# MPS2_SSE_200 register map
Vendor: ARM Ltd.; Series: ARMv8-M Mainline; File version: 1.0
CPU: CM33 r0p0, little endian, MPU, no FPU, 4 interrupt priority bits, 8 SAU regions
Registers are 32-bit, read-write, reset 0x0 unless marked. A register's access mark holds for its fields unless they carry their own. Offsets are from the block's base; [hi:lo] are bit positions; {n}, {i} and the like mark numbered series.

## SSP0 — SPI 0
Base 0x40205000
Same registers: SSP1 0x40206000, SSP2 0x40209000, SSP3 0x4020A000, SSP4 0x4020B000, SSP0_Secure 0x50205000, SSP1_Secure 0x50206000, SSP2_Secure 0x50209000, SSP3_Secure 0x5020A000, SSP4_Secure 0x5020B000
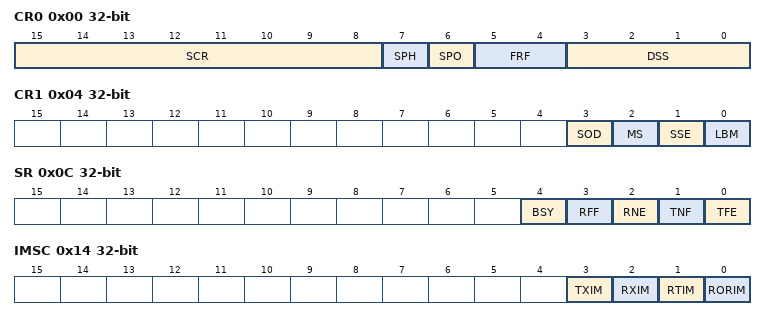
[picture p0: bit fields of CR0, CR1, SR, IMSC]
0x00 CR0 — Control register 0
  [15:8] SCR — Serial clock rate
  [7] SPH — SSPCLKOUT phase
  [6] SPO — SSPCLKOUT polarity
  [5:4] FRF — Frame format
    0=Motorola SPI frame format; 1=TI (TI synchronous serial frame format); 2=NM (National Microwire frame format)
  [3:0] DSS — Data Size Select
    {v}={v+1}-bit (v=3..15)
0x04 CR1 — Control register 1
  [3] SOD — Slave-mode output disable
    0=Enable (SSP can drive the SSPTXD output in slave mode); 1=Disable (SSP must not drive the SSPTXD output in slave mode)
  [2] MS — Master or slave mode select
    0=Master (Device configured as master, default); 1=Slave (Device configured as slave)
  [1] SSE — Synchronous serial port enable
    0=Disabled (SSP operation disabled); 1=Enabled (SSP operation enabled)
  [0] LBM — Loop back mode
    0=Normal serial port operation enabled; 1=Loopback (Output of transmit serial shifter is connected to input of receive serial shifter internally)
0x08 DR — Data register
  [15:0] Data — Transmit/Receive FIFO
0x0C SR — Status register
  [4] BSY — PrimeCell SSP busy flag
    0=Idle (SSP is idle); 1=Busy (SSP is currently transmitting and/or receiving a frame or the transmit FIFO is not empty)
  [3] RFF — Receive FIFO full
    0=NF (Receive FIFO is not full); 1=F (Receive FIFO is full)
  [2] RNE — Receive FIFO not empty
    0=E (Receive FIFO is empty); 1=NE (Receive FIFO is not empty)
  [1] TNF — Transmit FIFO not full
    0=F (Receive FIFO is full); 1=NF (Receive FIFO is not full)
  [0] TFE — Transmit FIFO empty
    0=NE (Receive FIFO is not empty); 1=E (Receive FIFO is empty)
0x10 CPSR — Clock prescale register
  [7:0] CPSDVSR — Clock prescale divisor
0x14 IMSC — Interrupt mask set or clear register
  [3] TXIM — Transmit FIFO interrupt mask
    0=Masked (Transmit FIFO half empty or less condition interrupt is masked); 1=Not Masked (Transmit FIFO half empty or less condition interrupt is not masked)
  [2] RXIM — Receive FIFO interrupt mask
    0=Masked (Receive FIFO half full or less condition interrupt is masked); 1=Not Masked (Receive FIFO half full or less condition interrupt is not masked)
  [1] RTIM — Receive timeout interrupt mask
    0=Masked (Receive FIFO not empty or no read prior to timeout period interrupt is masked); 1=Not Masked (Receive FIFO not empty or no read prior to timeout period interrupt is not masked)
  [0] RORIM — Receive overrun interrupt mask
    0=Masked (Receive FIFO written to while full condition interrupt is masked); 1=Not Masked (Receive FIFO written to while full condition interrupt is not masked)
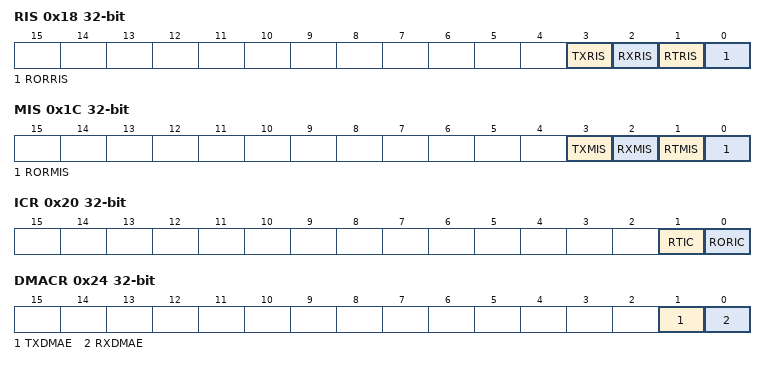
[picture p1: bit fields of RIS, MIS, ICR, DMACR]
0x18 RIS — Raw interrupt status register
  [3] TXRIS — transmit FIFO raw interrupt state
  [2] RXRIS — receive FIFO raw interrupt state
  [1] RTRIS — receive timeout raw interrupt state
  [0] RORRIS — receive over run raw interrupt state
0x1C MIS — Masked interrupt status register
  [3] TXMIS — transmit FIFO masked interrupt state
  [2] RXMIS — receive FIFO masked interrupt state
  [1] RTMIS — receive timeout masked interrupt state
  [0] RORMIS — receive over run masked interrupt state
0x20 ICR — Interrupt clear register
  [1] RTIC — Clears the SSPRTINTR interrupt
  [0] RORIC — Clears the SSPRORINTR interrupt
0x24 DMACR — DMA control register
  [1] TXDMAE — Transmit DMA Enable
  [0] RXDMAE — Receive DMA Enable
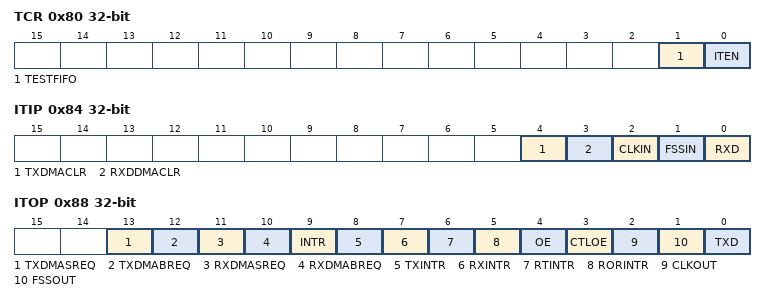
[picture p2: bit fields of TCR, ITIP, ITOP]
0x80 TCR — Test control register
  [1] TESTFIFO — Test FIFO enable
    0=Disabled (Normal operation); 1=Enabled (When this bit is 1, a write to the TDR writes data into the receive FIFO, and reads from the TDR reads data out of the transmit FIFO.)
  [0] ITEN — Integration test enable
    0=Disabled (Normal mode); 1=Enabled (The PrimeCell SSP is placed in integration test mode.)
0x84 ITIP — Integration test input register
  [4] TXDMACLR — Value to be driven on the intra-chip input
  [3] RXDDMACLR — Value to be driven on the intra-chip input
  [2] CLKIN — Return the value of CLKIN primary input
  [1] FSSIN — Return the value of FSSIN primary input
  [0] RXD — Return the value of RXD primary input
0x88 ITOP — Integration test output register
  [13] TXDMASREQ — Value on the TXDMASREQ line
  [12] TXDMABREQ — Value on the TXDMABREQ line
  [11] RXDMASREQ — Value on the TXDMASREQ line
  [10] RXDMABREQ — Value on the TXDMABREQ line
  [9] INTR — Value on the INTR line
  [8] TXINTR — Value on the TXINTR line
  [7] RXINTR — Value on the RXINTR line
  [6] RTINTR — Value on the RTINTR line
  [5] RORINTR — Value on the RORINTR line
  [4] OE — Value on the OE line
  [3] CTLOE — Value on the OE line
  [2] CLKOUT — Value on the CLKOUT line
  [1] FSSOUT — Value on the FSSOUT line
  [0] TXD — Value on the TXD line
0x8C TDR — Test data register
  [15:0] DATA — When the TESTFIFO signal is asserted, data is written into the receive FIFO and read out of the transmit FIFO
